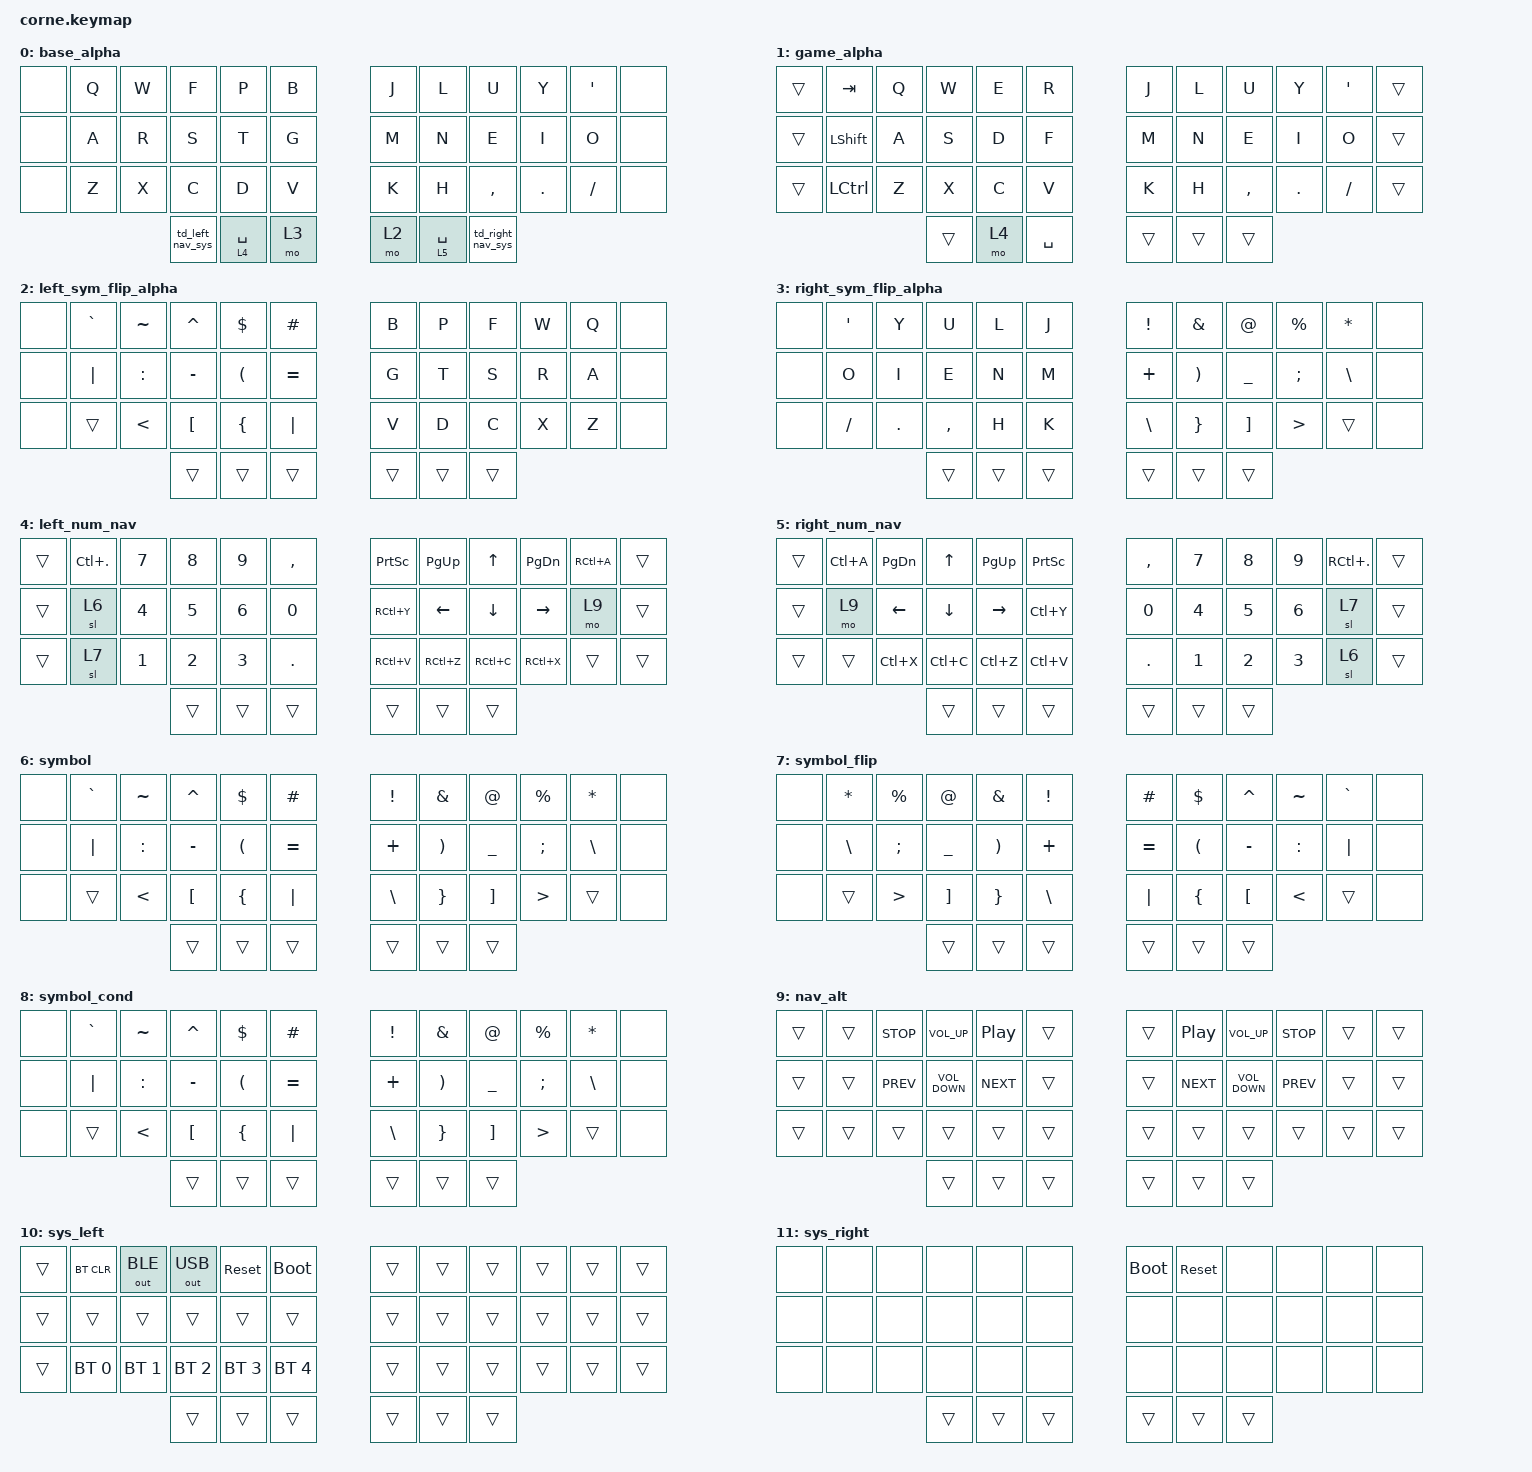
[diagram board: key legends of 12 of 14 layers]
#include <behaviors.dtsi>
#include <dt-bindings/zmk/bt.h>
#include <dt-bindings/zmk/keys.h>
#include <dt-bindings/zmk/outputs.h>

&caps_word { continue-list = <UNDERSCORE BACKSPACE DELETE MINUS>; };

&sk {
    release-after-ms = <500>;
    quick-release;
};

&lt {
    tapping-term-ms = <500>;
    flavor = "hold-preferred";
    hold-while-undecided;
};

/ {
    macros {
        // key press no repeat

        kpnr: kpnr {
            compatible = "zmk,behavior-macro-one-param";
            #binding-cells = <1>;
            bindings =
                <&macro_param_1to1>,
                <&macro_tap>,
                <&kp MACRO_PLACEHOLDER>;

            label = "Key tap macro";
        };

        // basic layer mod &lm <layer> <mod>

        lm: lm {
            compatible = "zmk,behavior-macro-two-param";
            wait-ms = <0>;
            tap-ms = <0>;
            #binding-cells = <2>;
            bindings =
                <&macro_param_1to1>,
                <&macro_press>,
                <&mo MACRO_PLACEHOLDER &macro_param_2to1>,
                <&macro_press>,
                <&kp MACRO_PLACEHOLDER>,
                <&macro_pause_for_release>,
                <&macro_param_2to1>,
                <&macro_release>,
                <&kp MACRO_PLACEHOLDER &macro_param_1to1>,
                <&macro_release>,
                <&mo MACRO_PLACEHOLDER>;
        };

        // layer mod left mod combos for additive mod combos

        lm_left: lm_left {
            compatible = "zmk,behavior-macro-one-param";
            wait-ms = <0>;
            tap-ms = <0>;
            #binding-cells = <1>;
            bindings =
                <&macro_press &mo 12 &macro_param_1to1>,
                <&macro_press>,
                <&kp MACRO_PLACEHOLDER>,
                <&macro_pause_for_release>,
                <&macro_param_1to1>,
                <&macro_release>,
                <&kp MACRO_PLACEHOLDER>,
                <&macro_release &mo 12>;
        };

        lm_left_nav: lm_left_nav {
            compatible = "zmk,behavior-macro-one-param";
            wait-ms = <0>;
            tap-ms = <0>;
            #binding-cells = <1>;
            bindings
                = <&macro_press &mo 5>
                , <&macro_param_1to1>
                , <&macro_tap &kp MACRO_PLACEHOLDER>
                , <&macro_pause_for_release>
                , <&macro_param_1to1>
                , <&macro_release &kp MACRO_PLACEHOLDER>
                , <&macro_release &mo 5>
                ;
        };

        // layer mod left mod combos for additive mod combos with sticky key

        lm_left_sk: lm_left_sk {
            compatible = "zmk,behavior-macro-one-param";
            wait-ms = <0>;
            tap-ms = <0>;
            #binding-cells = <1>;
            bindings
                = <&macro_press &mo 12>
                , <&macro_param_1to1>
                , <&macro_press &sk MACRO_PLACEHOLDER>
                , <&macro_pause_for_release>
                , <&macro_param_1to1>
                , <&macro_release &sk MACRO_PLACEHOLDER>
                , <&macro_release &mo 12>
                ;
        };

        // layer mod left special case for initiating tab combos

        lm_left_tab: lm_left_tab {
            compatible = "zmk,behavior-macro-two-param";
            wait-ms = <0>;
            tap-ms = <0>;
            #binding-cells = <2>;
            bindings
                = <&macro_press &mo 12>
                , <&macro_param_1to1>
                , <&macro_press &kp MACRO_PLACEHOLDER>
                , <&macro_param_2to1>
                , <&macro_tap &kp MACRO_PLACEHOLDER>
                , <&macro_pause_for_release>
                , <&macro_param_1to1>
                , <&macro_release &kp MACRO_PLACEHOLDER>
                , <&macro_release &mo 12>
                ;
        };

        // layer mod right mod combos for additive mod combos

        lm_right: lm_right {
            compatible = "zmk,behavior-macro-one-param";
            wait-ms = <0>;
            tap-ms = <0>;
            #binding-cells = <1>;
            bindings
                = <&macro_press &mo 13>
                , <&macro_param_1to1>
                , <&macro_press &kp MACRO_PLACEHOLDER>
                , <&macro_pause_for_release>
                , <&macro_param_1to1>
                , <&macro_release &kp MACRO_PLACEHOLDER>
                , <&macro_release &mo 13>
                ;
        };

        lm_right_nav: lm_right_nav {
            compatible = "zmk,behavior-macro-one-param";
            wait-ms = <0>;
            tap-ms = <0>;
            #binding-cells = <1>;
            bindings
                = <&macro_press &mo 4>
                , <&macro_param_1to1>
                , <&macro_tap &kp MACRO_PLACEHOLDER>
                , <&macro_pause_for_release>
                , <&macro_param_1to1>
                , <&macro_release &kp MACRO_PLACEHOLDER>
                , <&macro_release &mo 4>
                ;
        };

        // layer mod left special case for initiating tab combos

        lm_right_tab: lm_right_tab {
            compatible = "zmk,behavior-macro-two-param";
            wait-ms = <0>;
            tap-ms = <0>;
            #binding-cells = <2>;
            bindings
                = <&macro_press &mo 13>
                , <&macro_param_1to1>
                , <&macro_press &kp MACRO_PLACEHOLDER>
                , <&macro_param_2to1>
                , <&macro_tap &kp MACRO_PLACEHOLDER>
                , <&macro_pause_for_release>
                , <&macro_param_1to1>
                , <&macro_release &kp MACRO_PLACEHOLDER>
                , <&macro_release &mo 13>
                ;
        };

        // layer mod left mod combos for additive mod combos with sticky key

        lm_right_sk: lm_right_sk {
            compatible = "zmk,behavior-macro-one-param";
            wait-ms = <0>;
            tap-ms = <0>;
            #binding-cells = <1>;
            bindings
                = <&macro_press &mo 13>
                , <&macro_param_1to1>
                , <&macro_press &sk MACRO_PLACEHOLDER>
                , <&macro_pause_for_release>
                , <&macro_param_1to1>
                , <&macro_release &sk MACRO_PLACEHOLDER>
                , <&macro_release &mo 13>
                ;
        };
    };

    behaviors {
        lt_left: lt_left {
            compatible = "zmk,behavior-hold-tap";
            #binding-cells = <2>;
            flavor = "balanced";
            tapping-term-ms = <200>;
            quick-tap-ms = <300>;
            hold-while-undecided;
            bindings = <&mo>, <&kp>;
            require-prior-idle-ms = <100>;
        };

        lt_right: lt_right {
            compatible = "zmk,behavior-hold-tap";
            #binding-cells = <2>;
            flavor = "balanced";
            tapping-term-ms = <200>;
            quick-tap-ms = <300>;
            hold-while-undecided;
            bindings = <&mo>, <&kp>;
            hold-trigger-key-positions = <6 7 8 9 10 18 19 20 21 22 30 31 32 33 34>;
            require-prior-idle-ms = <100>;
        };

        // double tap hold num layer for function key layer

        td_left_nav_sys: td_left_nav_sys {
            compatible = "zmk,behavior-tap-dance";
            #binding-cells = <0>;
            tapping-term-ms = <500>;
            bindings = <&mo 5>, <&mo 10>;
        };

        td_right_nav_sys: td_right_nav_sys {
            compatible = "zmk,behavior-tap-dance";
            #binding-cells = <0>;
            tapping-term-ms = <500>;
            bindings = <&mo 4>, <&mo 11>;
        };

        // double tab left shift for caps_word

        td_ls: td_ls {
            compatible = "zmk,behavior-tap-dance";
            #binding-cells = <0>;
            tapping-term-ms = <500>;
            bindings = <&sk LEFT_SHIFT>, <&caps_word>;
        };

        // double tab right shift for caps_word

        td_rs: td_rs {
            compatible = "zmk,behavior-tap-dance";
            #binding-cells = <0>;
            tapping-term-ms = <500>;
            bindings = <&sk RIGHT_SHIFT>, <&caps_word>;
        };

        // basic hold tap

        ht: ht {
            compatible = "zmk,behavior-hold-tap";
            bindings = <&kp>, <&kp>;

            #binding-cells = <2>;
            tapping-term-ms = <200>;
            flavor = "tap-preferred";
        };

        // basic sticky hold taps

        sk_ht: sk_ht {
            compatible = "zmk,behavior-hold-tap";
            bindings = <&sk>, <&kp>;

            #binding-cells = <2>;
            tapping-term-ms = <100>;
            flavor = "tap-preferred";
        };

        ht_sk: ht_sk {
            compatible = "zmk,behavior-hold-tap";
            bindings = <&kp>, <&sk>;

            #binding-cells = <2>;
            tapping-term-ms = <100>;
            flavor = "tap-preferred";
        };

        // hold tap layer mod for left mod layer

        ht_lm_left: ht_lm_left {
            compatible = "zmk,behavior-hold-tap";
            bindings = <&lm_left>, <&kp>;

            #binding-cells = <2>;
            tapping-term-ms = <200>;
            flavor = "tap-preferred";
        };

        ht_lm_left_sk: ht_lm_left_sk {
            compatible = "zmk,behavior-hold-tap";
            bindings = <&lm_left_sk>, <&kp>;

            #binding-cells = <2>;
            tapping-term-ms = <100>;
            flavor = "tap-preferred";
        };

        // hold tap layer mod for right mod layer

        ht_lm_right: ht_lm_right {
            compatible = "zmk,behavior-hold-tap";
            bindings = <&lm_right>, <&kp>;

            #binding-cells = <2>;
            tapping-term-ms = <200>;
            flavor = "tap-preferred";
        };

        ht_lm_right_sk: ht_lm_right_sk {
            compatible = "zmk,behavior-hold-tap";
            bindings = <&lm_right_sk>, <&kp>;

            #binding-cells = <2>;
            tapping-term-ms = <100>;
            flavor = "tap-preferred";
        };

        // hold tap momentary layer + sticky layer

        ht_mo_sl: ht_mo_sl {
            compatible = "zmk,behavior-hold-tap";
            bindings = <&mo>, <&sl>;

            #binding-cells = <2>;
            tapping-term-ms = <500>;
            flavor = "hold-preferred";
        };
    };

    combos {
        compatible = "zmk,combos";

        L_GUI {
            bindings = <&ht_lm_left_sk LEFT_GUI LEFT_GUI>;
            key-positions = <17 16>;
            require-prior-idle-ms = <100>;
            timeout-ms = <30>;
        };

        L_GUI_SHIFT {
            bindings = <&ht_lm_left_sk LS(LEFT_GUI) LS(LEFT_GUI)>;
            key-positions = <17 3>;
            require-prior-idle-ms = <100>;
            timeout-ms = <30>;
        };

        L_GUI_CTRL {
            bindings = <&ht_lm_left_sk LC(LEFT_GUI) LC(LEFT_GUI)>;
            key-positions = <17 15>;
            require-prior-idle-ms = <100>;
            timeout-ms = <30>;
        };

        L_GUI_ALT {
            bindings = <&ht_lm_left_sk LA(LEFT_GUI) LA(LEFT_GUI)>;
            key-positions = <17 13>;
            require-prior-idle-ms = <100>;
            timeout-ms = <30>;
        };

        L_GUI_CTRL_SHIFT {
            bindings = <&ht_lm_left_sk LS(LC(LEFT_GUI)) LS(LC(LEFT_GUI))>;
            key-positions = <17 15 16>;
            require-prior-idle-ms = <100>;
            timeout-ms = <30>;
        };

        L_CTRL {
            bindings = <&ht_lm_left_sk LEFT_CONTROL LEFT_CONTROL>;
            key-positions = <14 15>;
            require-prior-idle-ms = <100>;
            timeout-ms = <30>;
        };

        L_ALT {
            bindings = <&ht_lm_left_sk LEFT_ALT LEFT_ALT>;
            key-positions = <13 14>;
            require-prior-idle-ms = <100>;
            timeout-ms = <30>;
        };

        L_ALT_SHIFT {
            bindings = <&ht_lm_left_sk LA(LEFT_SHIFT) LA(LEFT_SHIFT)>;
            key-positions = <16 13>;
            require-prior-idle-ms = <100>;
            timeout-ms = <30>;
        };

        L_SHIFT {
            bindings = <&td_ls>;
            key-positions = <16 15>;
            require-prior-idle-ms = <100>;
            timeout-ms = <30>;
        };

        L_CTRL_SHIFT {
            bindings = <&ht_lm_left_sk LC(LEFT_SHIFT) LC(LEFT_SHIFT)>;
            key-positions = <16 15 14>;
            require-prior-idle-ms = <100>;
            timeout-ms = <30>;
        };

        L_CTRL_ALT {
            bindings = <&ht_lm_left_sk LC(LEFT_ALT) LC(LEFT_ALT)>;
            key-positions = <13 14 15>;
            require-prior-idle-ms = <100>;
            timeout-ms = <30>;
        };

        L_CTRL_ALT_SHIFT {
            bindings = <&ht_lm_left_sk LC(LA(LEFT_SHIFT)) LC(LA(LEFT_SHIFT))>;
            key-positions = <13 16 14 15>;
            require-prior-idle-ms = <100>;
            timeout-ms = <30>;
        };

        L_TAB {
            bindings = <&kp TAB>;
            key-positions = <4 5>;
            require-prior-idle-ms = <100>;
            timeout-ms = <30>;
        };

        L_SHIFT_TAB {
            bindings = <&kp LS(TAB)>;
            key-positions = <4 3 5>;
            require-prior-idle-ms = <100>;
            timeout-ms = <30>;
        };

        L_ALT_TAB {
            bindings = <&lm_left_tab LEFT_ALT TAB>;
            key-positions = <4 13>;
            require-prior-idle-ms = <100>;
            timeout-ms = <30>;
            slow-release;
        };

        L_ALT_SHIFT_TAB {
            bindings = <&lm_left_tab LEFT_ALT LS(TAB)>;
            key-positions = <4 13 3>;
            require-prior-idle-ms = <100>;
            timeout-ms = <30>;
            slow-release;
        };

        L_CTRL_TAB {
            bindings = <&lm_left_tab LEFT_CONTROL TAB>;
            key-positions = <4 14>;
            require-prior-idle-ms = <100>;
            timeout-ms = <30>;
            slow-release;
        };

        L_CTRL_SHIFT_TAB {
            bindings = <&lm_left_tab LEFT_CONTROL LS(TAB)>;
            key-positions = <4 14 3>;
            require-prior-idle-ms = <100>;
            timeout-ms = <30>;
            slow-release;
        };

        L_GUI_TAB {
            bindings = <&lm_left_tab LEFT_GUI TAB>;
            key-positions = <17 4>;
            require-prior-idle-ms = <100>;
            timeout-ms = <30>;
            slow-release;
        };

        L_GUI_SHIFT_TAB {
            bindings = <&lm_left_tab LEFT_GUI LS(TAB)>;
            key-positions = <17 3 4>;
            require-prior-idle-ms = <100>;
            timeout-ms = <30>;
            slow-release;
        };

        L_ESC {
            bindings = <&kp ESCAPE>;
            key-positions = <1 2>;
            require-prior-idle-ms = <100>;
            timeout-ms = <30>;
        };

        L_DEL {
            bindings = <&kp DELETE>;
            key-positions = <3 2>;
            require-prior-idle-ms = <100>;
            timeout-ms = <30>;
        };

        L_BACKSPACE {
            bindings = <&kp BACKSPACE>;
            key-positions = <4 3>;
            require-prior-idle-ms = <100>;
            timeout-ms = <30>;
        };

        L_ENTER {
            bindings = <&kp ENTER>;
            key-positions = <27 28>;
            require-prior-idle-ms = <100>;
            timeout-ms = <30>;
        };

        L_SHIFT_ENTER {
            bindings = <&kp RS(ENTER)>;
            key-positions = <28 27 26>;
            require-prior-idle-ms = <100>;
            timeout-ms = <30>;
        };

        L_SYM {
            bindings = <&sl 6>;
            key-positions = <37 13>;
            require-prior-idle-ms = <100>;
            timeout-ms = <30>;
        };

        L_SYM_FLIP {
            bindings = <&sl 7>;
            key-positions = <37 25>;
            require-prior-idle-ms = <100>;
            timeout-ms = <30>;
        };

        L_NAV_UP {
            bindings = <&lm_left_nav UP_ARROW>;
            key-positions = <37 3>;
            require-prior-idle-ms = <100>;
            timeout-ms = <30>;
            slow-release;
        };

        L_NAV_DOWN {
            bindings = <&lm_left_nav DOWN_ARROW>;
            key-positions = <37 15>;
            require-prior-idle-ms = <100>;
            timeout-ms = <30>;
            slow-release;
        };

        L_NAV_LEFT {
            bindings = <&lm_left_nav LEFT_ARROW>;
            key-positions = <37 14>;
            require-prior-idle-ms = <100>;
            timeout-ms = <30>;
            slow-release;
        };

        L_NAV_RIGHT {
            bindings = <&lm_left_nav RIGHT_ARROW>;
            key-positions = <37 16>;
            require-prior-idle-ms = <100>;
            timeout-ms = <30>;
            slow-release;
        };

        L_NAV_PASTE {
            bindings = <&lm_left_nav LC(V)>;
            key-positions = <37 29>;
            require-prior-idle-ms = <100>;
            timeout-ms = <30>;
            slow-release;
        };

        L_NAV_REDO {
            bindings = <&lm_left_nav LC(Y)>;
            key-positions = <37 17>;
            require-prior-idle-ms = <100>;
            timeout-ms = <30>;
            slow-release;
        };

        L_NAV_COPY {
            bindings = <&lm_left_nav LC(C)>;
            key-positions = <37 27>;
            require-prior-idle-ms = <100>;
            timeout-ms = <30>;
            slow-release;
        };

        L_NAV_CUT {
            bindings = <&lm_left_nav LC(X)>;
            key-positions = <37 26>;
            require-prior-idle-ms = <100>;
            timeout-ms = <30>;
            slow-release;
        };

        L_NAV_UNDO {
            bindings = <&lm_left_nav LC(Z)>;
            key-positions = <37 28>;
            require-prior-idle-ms = <100>;
            timeout-ms = <30>;
            slow-release;
        };

        L_NAV_SELECT_ALL {
            bindings = <&lm_left_nav LC(A)>;
            key-positions = <37 1>;
            require-prior-idle-ms = <100>;
            timeout-ms = <30>;
            slow-release;
        };

        R_GUI {
            bindings = <&ht_lm_right_sk RIGHT_GUI RIGHT_GUI>;
            key-positions = <18 19>;
            require-prior-idle-ms = <100>;
            timeout-ms = <30>;
        };

        R_GUI_SHIFT {
            bindings = <&ht_lm_right_sk RS(RIGHT_GUI) RS(RIGHT_GUI)>;
            key-positions = <18 8>;
            require-prior-idle-ms = <100>;
            timeout-ms = <30>;
        };

        R_GUI_CTRL {
            bindings = <&ht_lm_right_sk RC(RIGHT_GUI) RC(RIGHT_GUI)>;
            key-positions = <18 20>;
            require-prior-idle-ms = <100>;
            timeout-ms = <30>;
        };

        R_GUI_ALT {
            bindings = <&ht_lm_right_sk RA(RIGHT_GUI) RA(RIGHT_GUI)>;
            key-positions = <18 22>;
            require-prior-idle-ms = <100>;
            timeout-ms = <30>;
        };

        R_GUI_CTRL_SHIFT {
            bindings = <&ht_lm_right_sk RS(RC(RIGHT_GUI)) RS(RC(RIGHT_GUI))>;
            key-positions = <18 20 19>;
            require-prior-idle-ms = <100>;
            timeout-ms = <30>;
        };

        R_CTRL {
            bindings = <&ht_lm_right_sk RIGHT_CONTROL RIGHT_CONTROL>;
            key-positions = <21 20>;
            require-prior-idle-ms = <100>;
            timeout-ms = <30>;
        };

        R_ALT {
            bindings = <&ht_lm_right_sk RIGHT_ALT RIGHT_ALT>;
            key-positions = <22 21>;
            require-prior-idle-ms = <100>;
            timeout-ms = <30>;
        };

        R_ALT_SHIFT {
            bindings = <&ht_lm_right_sk RA(LEFT_SHIFT) RA(LEFT_SHIFT)>;
            key-positions = <19 22>;
            require-prior-idle-ms = <100>;
            timeout-ms = <30>;
        };

        R_SHIFT {
            bindings = <&td_rs>;
            key-positions = <20 19>;
            require-prior-idle-ms = <100>;
            timeout-ms = <30>;
        };

        R_CTRL_SHIFT {
            bindings = <&ht_lm_right_sk RC(RIGHT_SHIFT) RC(RIGHT_SHIFT)>;
            key-positions = <19 20 21>;
            require-prior-idle-ms = <100>;
            timeout-ms = <30>;
        };

        R_CTRL_ALT {
            bindings = <&ht_lm_right_sk RC(RIGHT_ALT) RC(RIGHT_ALT)>;
            key-positions = <22 21 20>;
            require-prior-idle-ms = <100>;
            timeout-ms = <30>;
        };

        R_CTRL_ALT_SHIFT {
            bindings = <&ht_lm_right_sk RC(RA(RIGHT_SHIFT)) RC(RA(RIGHT_SHIFT))>;
            key-positions = <19 22 21 20>;
            require-prior-idle-ms = <100>;
            timeout-ms = <30>;
        };

        R_TAB {
            bindings = <&kp TAB>;
            key-positions = <6 7>;
            require-prior-idle-ms = <100>;
            timeout-ms = <30>;
        };

        R_SHIFT_TAB {
            bindings = <&kp LS(TAB)>;
            key-positions = <6 7 8>;
            require-prior-idle-ms = <100>;
            timeout-ms = <30>;
        };

        R_ALT_TAB {
            bindings = <&lm_right_tab LEFT_ALT TAB>;
            key-positions = <7 22>;
            require-prior-idle-ms = <100>;
            timeout-ms = <30>;
            slow-release;
        };

        R_ALT_SHIFT_TAB {
            bindings = <&lm_right_tab LEFT_ALT LS(TAB)>;
            key-positions = <7 8 22>;
            require-prior-idle-ms = <100>;
            timeout-ms = <30>;
            slow-release;
        };

        R_CTRL_TAB {
            bindings = <&lm_right_tab LEFT_CONTROL TAB>;
            key-positions = <7 21>;
            require-prior-idle-ms = <100>;
            timeout-ms = <30>;
            slow-release;
        };

        R_CTRL_SHIFT_TAB {
            bindings = <&lm_right_tab LEFT_CONTROL LS(TAB)>;
            key-positions = <7 8 21>;
            require-prior-idle-ms = <100>;
            timeout-ms = <30>;
            slow-release;
        };

        R_GUI_TAB {
            bindings = <&lm_right_tab RIGHT_GUI TAB>;
            key-positions = <18 7>;
            require-prior-idle-ms = <100>;
            timeout-ms = <30>;
            slow-release;
        };

        R_GUI_SHIFT_TAB {
            bindings = <&lm_right_tab LEFT_GUI LS(TAB)>;
            key-positions = <18 7 8>;
            require-prior-idle-ms = <100>;
            timeout-ms = <30>;
            slow-release;
        };

        R_ESC {
            bindings = <&kp ESCAPE>;
            key-positions = <10 9>;
            require-prior-idle-ms = <100>;
            timeout-ms = <30>;
        };

        R_DEL {
            bindings = <&kp DELETE>;
            key-positions = <8 9>;
            require-prior-idle-ms = <100>;
            timeout-ms = <30>;
        };

        R_BACKSPACE {
            bindings = <&kp BACKSPACE>;
            key-positions = <7 8>;
            require-prior-idle-ms = <100>;
            timeout-ms = <30>;
        };

        R_ENTER {
            bindings = <&kp ENTER>;
            key-positions = <31 32>;
            require-prior-idle-ms = <100>;
            timeout-ms = <30>;
        };

        R_SHIFT_ENTER {
            bindings = <&kp RS(ENTER)>;
            key-positions = <31 32 33>;
            require-prior-idle-ms = <100>;
            timeout-ms = <30>;
        };

        R_SYM {
            bindings = <&sl 7>;
            key-positions = <40 22>;
            require-prior-idle-ms = <100>;
            timeout-ms = <30>;
        };

        R_SYM_FLIP {
            bindings = <&sl 6>;
            key-positions = <40 34>;
            require-prior-idle-ms = <100>;
            timeout-ms = <30>;
        };

        R_NAV_UP {
            bindings = <&lm_right_nav UP_ARROW>;
            key-positions = <8 40>;
            require-prior-idle-ms = <100>;
            timeout-ms = <30>;
            slow-release;
        };

        R_NAV_DOWN {
            bindings = <&lm_right_nav DOWN_ARROW>;
            key-positions = <20 40>;
            require-prior-idle-ms = <100>;
            timeout-ms = <30>;
            slow-release;
        };

        R_NAV_LEFT {
            bindings = <&lm_right_nav LEFT_ARROW>;
            key-positions = <40 19>;
            require-prior-idle-ms = <100>;
            timeout-ms = <30>;
            slow-release;
        };

        R_NAV_RIGHT {
            bindings = <&lm_right_nav RIGHT_ARROW>;
            key-positions = <40 21>;
            require-prior-idle-ms = <100>;
            timeout-ms = <30>;
            slow-release;
        };

        R_NAV_PASTE {
            bindings = <&lm_right_nav RC(V)>;
            key-positions = <40 30>;
            require-prior-idle-ms = <100>;
            timeout-ms = <30>;
            slow-release;
        };

        R_NAV_REDO {
            bindings = <&lm_right_nav RC(Y)>;
            key-positions = <40 18>;
            require-prior-idle-ms = <100>;
            timeout-ms = <30>;
            slow-release;
        };

        R_NAV_COPY {
            bindings = <&lm_right_nav RC(C)>;
            key-positions = <40 32>;
            require-prior-idle-ms = <100>;
            timeout-ms = <30>;
            slow-release;
        };

        R_NAV_CUT {
            bindings = <&lm_right_nav RC(X)>;
            key-positions = <40 33>;
            require-prior-idle-ms = <100>;
            timeout-ms = <30>;
            slow-release;
        };

        R_NAV_UNDO {
            bindings = <&lm_right_nav RC(Z)>;
            key-positions = <40 31>;
            require-prior-idle-ms = <100>;
            timeout-ms = <30>;
            slow-release;
        };

        R_NAV_SELECT_ALL {
            bindings = <&lm_right_nav RC(A)>;
            key-positions = <40 10>;
            require-prior-idle-ms = <100>;
            timeout-ms = <30>;
            slow-release;
        };

        L_R_SHIFT {
            bindings = <&kp CAPSLOCK>;
            key-positions = <16 15 19 20>;
            require-prior-idle-ms = <100>;
            timeout-ms = <30>;
        };

        TOG_GAME_MODE {
            bindings = <&tog 1>;
            key-positions = <3 14 16 38>;
            timeout-ms = <30>;
        };
    };

    keymap {
        compatible = "zmk,keymap";

        base_alpha {
            bindings = <
&none  &kp Q  &kp W  &kp F             &kp P             &kp B    &kp J  &kp L              &kp U              &kp Y    &kp SINGLE_QUOTE  &none
&none  &kp A  &kp R  &kp S             &kp T             &kp G    &kp M  &kp N              &kp E              &kp I    &kp O             &none
&none  &kp Z  &kp X  &kp C             &kp D             &kp V    &kp K  &kp H              &kp COMMA          &kp DOT  &kp SLASH         &none
                     &td_left_nav_sys  &lt_left 4 SPACE  &mo 3    &mo 2  &lt_right 5 SPACE  &td_right_nav_sys
            >;
        };

        game_alpha {
            bindings = <
&trans  &kp TAB    &kp Q  &kp W   &kp E  &kp R        &kp J   &kp L   &kp U      &kp Y    &kp APOS  &trans
&trans  &kp LSHFT  &kp A  &kp S   &kp D  &kp F        &kp M   &kp N   &kp E      &kp I    &kp O     &trans
&trans  &kp LCTRL  &kp Z  &kp X   &kp C  &kp V        &kp K   &kp H   &kp COMMA  &kp DOT  &kp FSLH  &trans
                          &trans  &mo 4  &kp SPACE    &trans  &trans  &trans
            >;
        };

        left_sym_flip_alpha {
            bindings = <
&none  &kp GRAVE  &kp TILDE      &kp CARET         &kp DOLLAR            &kp HASH     &kp B   &kp P   &kp F   &kp W  &kp Q  &none
&none  &kp PIPE   &kp COLON      &kp MINUS         &kp LEFT_PARENTHESIS  &kp EQUAL    &kp G   &kp T   &kp S   &kp R  &kp A  &none
&none  &trans     &kp LESS_THAN  &kp LEFT_BRACKET  &kp LEFT_BRACE        &kp PIPE     &kp V   &kp D   &kp C   &kp X  &kp Z  &none
                                 &trans            &trans                &trans       &trans  &trans  &trans
            >;
        };

        right_sym_flip_alpha {
            bindings = <
&none  &kp APOS  &kp Y    &kp U      &kp L   &kp J     &kp EXCLAMATION  &kp AMPERSAND          &kp AT_SIGN        &kp PERCENT       &kp ASTERISK   &none
&none  &kp O     &kp I    &kp E      &kp N   &kp M     &kp PLUS         &kp RIGHT_PARENTHESIS  &kp UNDERSCORE     &kp SEMICOLON     &kp BACKSLASH  &none
&none  &kp FSLH  &kp DOT  &kp COMMA  &kp H   &kp K     &kp BACKSLASH    &kp RIGHT_BRACE        &kp RIGHT_BRACKET  &kp GREATER_THAN  &trans         &none
                          &trans     &trans  &trans    &trans           &trans                 &trans
            >;
        };

        left_num_nav {
            bindings = <
&trans  &kp LC(DOT)  &kp N7  &kp N8  &kp N9  &kp COMMA    &kp PRINTSCREEN  &kp PAGE_UP     &kp UP_ARROW    &kp PAGE_DOWN    &kp RC(A)  &trans
&trans  &sl 6        &kp N4  &kp N5  &kp N6  &kp N0       &kp RC(Y)        &kp LEFT_ARROW  &kp DOWN_ARROW  &kp RIGHT_ARROW  &mo 9      &trans
&trans  &sl 7        &kp N1  &kp N2  &kp N3  &kp DOT      &kp RC(V)        &kp RC(Z)       &kp RC(C)       &kp RC(X)        &trans     &trans
                             &trans  &trans  &trans       &trans           &trans          &trans
            >;
        };

        right_num_nav {
            bindings = <
&trans  &kp LC(A)  &kp PAGE_DOWN   &kp UP_ARROW    &kp PAGE_UP      &kp PRINTSCREEN    &kp COMMA  &kp N7  &kp N8  &kp N9  &kp RC(DOT)  &trans
&trans  &mo 9      &kp LEFT_ARROW  &kp DOWN_ARROW  &kp RIGHT_ARROW  &kp LC(Y)          &kp N0     &kp N4  &kp N5  &kp N6  &sl 7        &trans
&trans  &trans     &kp LC(X)       &kp LC(C)       &kp LC(Z)        &kp LC(V)          &kp DOT    &kp N1  &kp N2  &kp N3  &sl 6        &trans
                                   &trans          &trans           &trans             &trans     &trans  &trans
            >;
        };

        symbol {
            bindings = <
&none  &kp GRAVE  &kp TILDE      &kp CARET         &kp DOLLAR            &kp HASH     &kp EXCLAMATION  &kp AMPERSAND          &kp AT_SIGN        &kp PERCENT       &kp ASTERISK   &none
&none  &kp PIPE   &kp COLON      &kp MINUS         &kp LEFT_PARENTHESIS  &kp EQUAL    &kp PLUS         &kp RIGHT_PARENTHESIS  &kp UNDERSCORE     &kp SEMICOLON     &kp BACKSLASH  &none
&none  &trans     &kp LESS_THAN  &kp LEFT_BRACKET  &kp LEFT_BRACE        &kp PIPE     &kp BACKSLASH    &kp RIGHT_BRACE        &kp RIGHT_BRACKET  &kp GREATER_THAN  &trans         &none
                                 &trans            &trans                &trans       &trans           &trans                 &trans
            >;
        };

        symbol_flip {
            bindings = <
&none  &kp ASTERISK   &kp PERCENT       &kp AT_SIGN        &kp AMPERSAND          &kp EXCLAMATION    &kp HASH   &kp DOLLAR            &kp CARET         &kp TILDE      &kp GRAVE  &none
&none  &kp BACKSLASH  &kp SEMICOLON     &kp UNDERSCORE     &kp RIGHT_PARENTHESIS  &kp PLUS           &kp EQUAL  &kp LEFT_PARENTHESIS  &kp MINUS         &kp COLON      &kp PIPE   &none
&none  &trans         &kp GREATER_THAN  &kp RIGHT_BRACKET  &kp RIGHT_BRACE        &kp BACKSLASH      &kp PIPE   &kp LEFT_BRACE        &kp LEFT_BRACKET  &kp LESS_THAN  &trans     &none
                                        &trans             &trans                 &trans             &trans     &trans                &trans
            >;
        };

        symbol_cond {
            bindings = <
&none  &kp GRAVE  &kp TILDE      &kp CARET         &kp DOLLAR            &kp HASH     &kp EXCLAMATION  &kp AMPERSAND          &kp AT_SIGN        &kp PERCENT       &kp ASTERISK   &none
&none  &kp PIPE   &kp COLON      &kp MINUS         &kp LEFT_PARENTHESIS  &kp EQUAL    &kp PLUS         &kp RIGHT_PARENTHESIS  &kp UNDERSCORE     &kp SEMICOLON     &kp BACKSLASH  &none
&none  &trans     &kp LESS_THAN  &kp LEFT_BRACKET  &kp LEFT_BRACE        &kp PIPE     &kp BACKSLASH    &kp RIGHT_BRACE        &kp RIGHT_BRACKET  &kp GREATER_THAN  &trans         &none
                                 &trans            &trans                &trans       &trans           &trans                 &trans
            >;
        };

        nav_alt {
            bindings = <
&trans  &trans  &kp C_STOP  &kp C_VOLUME_UP    &kp C_PLAY_PAUSE  &trans    &trans  &kp C_PLAY_PAUSE  &kp C_VOLUME_UP    &kp C_STOP  &trans  &trans
&trans  &trans  &kp C_PREV  &kp C_VOLUME_DOWN  &kp C_NEXT        &trans    &trans  &kp C_NEXT        &kp C_VOLUME_DOWN  &kp C_PREV  &trans  &trans
&trans  &trans  &trans      &trans             &trans            &trans    &trans  &trans            &trans             &trans      &trans  &trans
                            &trans             &trans            &trans    &trans  &trans            &trans
            >;
        };

        sys_left {
            bindings = <
&trans  &bt BT_CLR    &out OUT_BLE  &out OUT_USB  &sys_reset    &bootloader     &trans  &trans  &trans  &trans  &trans  &trans
&trans  &trans        &trans        &trans        &trans        &trans          &trans  &trans  &trans  &trans  &trans  &trans
&trans  &bt BT_SEL 0  &bt BT_SEL 1  &bt BT_SEL 2  &bt BT_SEL 3  &bt BT_SEL 4    &trans  &trans  &trans  &trans  &trans  &trans
                                    &trans        &trans        &trans          &trans  &trans  &trans
            >;
        };

        sys_right {
            bindings = <
&none  &none  &none  &none   &none   &none     &bootloader  &sys_reset  &none   &none  &none  &none
&none  &none  &none  &none   &none   &none     &none        &none       &none   &none  &none  &none
&none  &none  &none  &none   &none   &none     &none        &none       &none   &none  &none  &none
                     &trans  &trans  &trans    &trans       &trans      &trans
            >;
        };

        mod_layer_left {
            bindings = <
&trans  &trans        &trans            &kp LEFT_SHIFT  &kp TAB         &trans          &trans  &trans  &trans  &trans  &trans  &trans
&trans  &sk LEFT_ALT  &sk LEFT_CONTROL  &sk LCTRL       &sk LEFT_SHIFT  &sk LEFT_GUI    &trans  &trans  &trans  &trans  &trans  &trans
&trans  &trans        &trans            &trans          &trans          &trans          &trans  &trans  &trans  &trans  &trans  &trans
                                        &trans          &trans          &trans          &trans  &trans  &trans
            >;
        };

        mod_layer_right {
            bindings = <
&trans  &trans  &trans  &trans  &trans  &trans    &trans         &kp TAB          &kp RIGHT_SHIFT    &trans             &trans         &trans
&trans  &trans  &trans  &trans  &trans  &trans    &sk RIGHT_GUI  &sk RIGHT_SHIFT  &sk RIGHT_CONTROL  &sk RIGHT_CONTROL  &sk RIGHT_ALT  &trans
&trans  &trans  &trans  &trans  &trans  &trans    &trans         &trans           &trans             &trans             &trans         &trans
                        &trans  &trans  &trans    &trans         &trans           &trans
            >;
        };
    };

    conditional_layers {
        compatible = "zmk,conditional-layers";

        sym {
            if-layers = <2 3>;
            then-layer = <8>;
        };
    };
};
